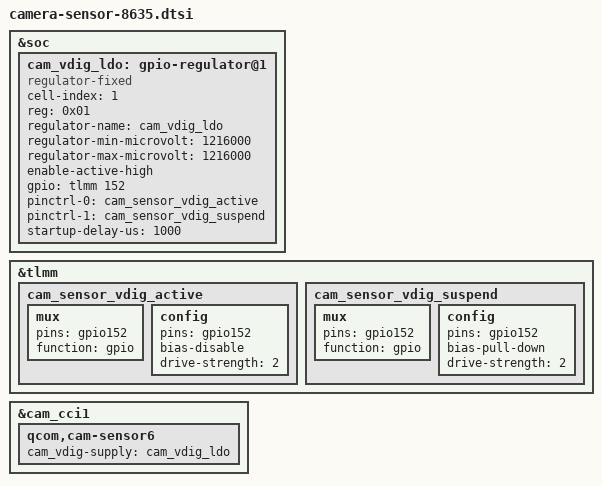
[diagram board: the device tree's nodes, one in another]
#include "camera-sensor-8631.dtsi"

&soc {
	cam_vdig_ldo: gpio-regulator@1 {
		cell-index = <1>;
		compatible = "regulator-fixed";
		reg = <0x01>;
		regulator-name = "cam_vdig_ldo";
		regulator-min-microvolt = <1216000>;
		regulator-max-microvolt = <1216000>;
		enable-active-high;
		gpio = <&tlmm 152 0>;
		pinctrl-names = "cam_default", "cam_suspend";
		pinctrl-0 = <&cam_sensor_vdig_active>;
		pinctrl-1 = <&cam_sensor_vdig_suspend>;
		startup-delay-us = <1000>;
	};
};

&tlmm {
	cam_sensor_vdig_active: cam_sensor_vdig_active {
		mux {
			pins = "gpio152";
			function = "gpio";
		};

		config {
			pins = "gpio152";
			bias-disable; /* No PULL */
			drive-strength = <2>; /* 2 MA */
		};
	};

	cam_sensor_vdig_suspend: cam_sensor_vdig_suspend {
		mux {
			pins = "gpio152";
			function = "gpio";
		};

		config {
			pins = "gpio152";
			bias-pull-down; /* PULL DOWN */
			drive-strength = <2>; /* 2 MA */
		};
	};
};

/* cci1: i2c2、i2c3 */
&cam_cci1 {
	/* rear wide senosr */
	qcom,cam-sensor6 {
		cam_vdig-supply = <&cam_vdig_ldo>; /* dvdd ldo 1.216v*/
	};
};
